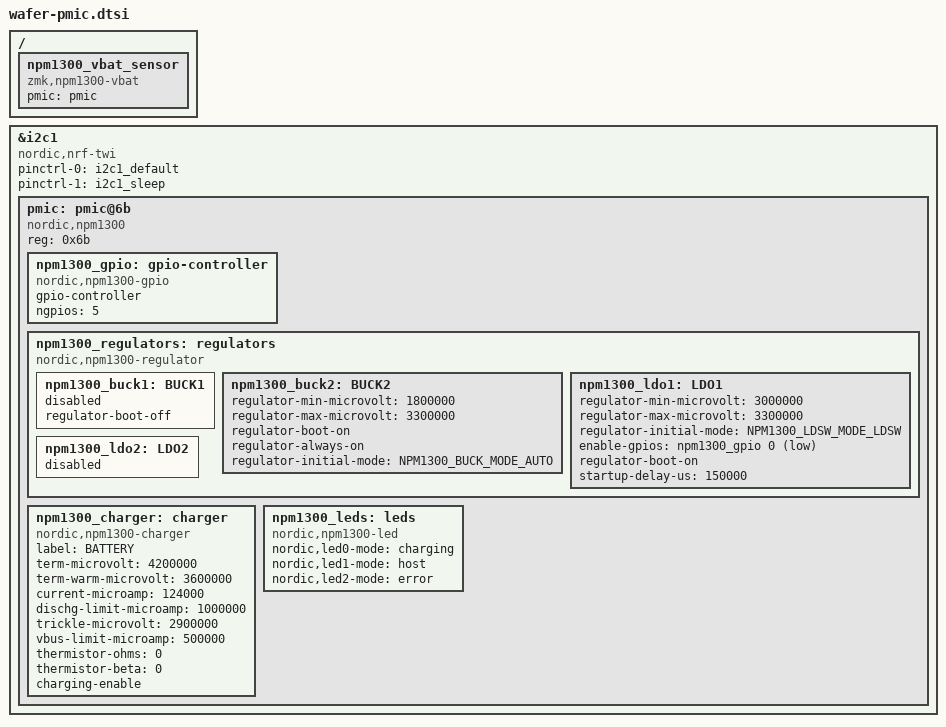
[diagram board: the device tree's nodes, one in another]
/*
 * Copyright (c) 2020 The ZMK Contributors
 * SPDX-License-Identifier: MIT
 */

#include <dt-bindings/regulator/npm1300.h>

/* I2C1: nPM1300, BAT_I2C_SCL=P0.02, BAT_I2C_SDA=P0.31 */

&i2c1 {
    compatible = "nordic,nrf-twi";
    status = "okay";
    pinctrl-0 = <&i2c1_default>;
    pinctrl-1 = <&i2c1_sleep>;
    pinctrl-names = "default", "sleep";

    pmic: pmic@6b {
        compatible = "nordic,npm1300";
        reg = <0x6b>;
        status = "okay";

        npm1300_gpio: gpio-controller {
            compatible = "nordic,npm1300-gpio";
            gpio-controller;
            #gpio-cells = <2>;
            ngpios = <5>;
        };

        npm1300_regulators: regulators {
            compatible = "nordic,npm1300-regulator";

            npm1300_buck1: BUCK1 {
                regulator-boot-off;
                status = "disabled";
            };

            npm1300_buck2: BUCK2 {
                regulator-min-microvolt = <1800000>;
                regulator-max-microvolt = <3300000>;
                regulator-boot-on;
                regulator-always-on;
                regulator-initial-mode = <NPM1300_BUCK_MODE_AUTO>;
            };

            npm1300_ldo1: LDO1 {
                regulator-min-microvolt = <3000000>;
                regulator-max-microvolt = <3300000>;
                regulator-initial-mode = <NPM1300_LDSW_MODE_LDSW>;
                enable-gpios = <&npm1300_gpio 0 GPIO_ACTIVE_LOW>;
                regulator-boot-on;
                /* EXT_POWER waits before nPM1300 finishes configuring GPIO
                 * control. If LDO1 was initially off, give it the same settle
                 * time here before the display initializes. */
                startup-delay-us = <150000>;
            };

            /* Free LDO */
            npm1300_ldo2: LDO2 {
                status = "disabled";
            };
        };

        npm1300_charger: charger {
            compatible = "nordic,npm1300-charger";
            label = "BATTERY";
            status = "okay";

            term-microvolt = <4200000>;
            term-warm-microvolt = <3600000>;
            current-microamp = <124000>;
            dischg-limit-microamp = <1000000>;
            trickle-microvolt = <2900000>;
            vbus-limit-microamp = <500000>;
            thermistor-ohms = <0>;
            thermistor-beta = <0>;
            charging-enable;
        };

        npm1300_leds: leds {
            compatible = "nordic,npm1300-led";
            nordic,led0-mode = "charging";
            nordic,led1-mode = "host";
            nordic,led2-mode = "error";
        };
    };
};

/*
 * ZMK custom sensor: triggers VBAT measurement on the nPM1300 PMIC and
 * exposes SENSOR_CHAN_VOLTAGE in volts. Pair with
 * CONFIG_ZMK_BATTERY_REPORTING_FETCH_MODE_LITHIUM_VOLTAGE so ZMK derives
 * the battery percentage from the lithium curve.
 */
/ {
	npm1300_vbat_sensor: npm1300_vbat_sensor {
		compatible = "zmk,npm1300-vbat";
		pmic = <&pmic>;
		status = "okay";
	};
};
